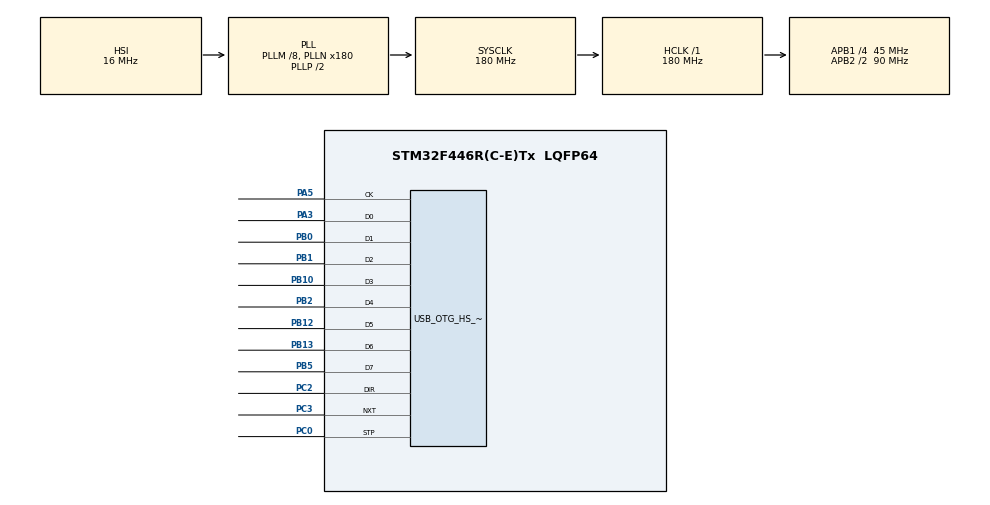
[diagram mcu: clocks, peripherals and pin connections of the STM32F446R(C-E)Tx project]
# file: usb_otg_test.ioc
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Mcu.Family=STM32F4
Mcu.Name=STM32F446R(C-E)Tx
Mcu.Package=LQFP64
NVIC.PriorityGroup=NVIC_PRIORITYGROUP_4
PA3.Mode=Device_HS
PA3.Signal=USB_OTG_HS_ULPI_D0
PA5.Mode=Device_HS
PA5.Signal=USB_OTG_HS_ULPI_CK
PB0.Mode=Device_HS
PB0.Signal=USB_OTG_HS_ULPI_D1
PB1.Mode=Device_HS
PB1.Signal=USB_OTG_HS_ULPI_D2
PB10.Mode=Device_HS
PB10.Signal=USB_OTG_HS_ULPI_D3
PB12.Mode=Device_HS
PB12.Signal=USB_OTG_HS_ULPI_D5
PB13.Mode=Device_HS
PB13.Signal=USB_OTG_HS_ULPI_D6
PB2.Mode=Device_HS
PB2.Signal=USB_OTG_HS_ULPI_D4
PB5.Mode=Device_HS
PB5.Signal=USB_OTG_HS_ULPI_D7
PC0.Mode=Device_HS
PC0.Signal=USB_OTG_HS_ULPI_STP
PC2.Mode=Device_HS
PC2.Signal=USB_OTG_HS_ULPI_DIR
PC3.Mode=Device_HS
PC3.Signal=USB_OTG_HS_ULPI_NXT
ProjectManager.HeapSize=0x200
ProjectManager.StackSize=0x400
ProjectManager.TargetToolchain=SW4STM32
RCC.AHBFreq_Value=180000000
RCC.APB1CLKDivider=RCC_HCLK_DIV4
RCC.APB1Freq_Value=45000000
RCC.APB1TimFreq_Value=90000000
RCC.APB2CLKDivider=RCC_HCLK_DIV2
RCC.APB2Freq_Value=90000000
RCC.APB2TimFreq_Value=180000000
RCC.CortexFreq_Value=180000000
RCC.HCLKFreq_Value=180000000
RCC.PLLM=8
RCC.PLLN=180
RCC.SYSCLKFreq_VALUE=180000000
RCC.SYSCLKSource=RCC_SYSCLKSOURCE_PLLCLK
RCC.USBFreq_Value=180000000
RCC.VCOOutputFreq_Value=360000000
USB_OTG_HS.DeviceSpeed-Device_HS=PCD_SPEED_FULL
USB_OTG_HS.VirtualMode-Device_HS=Device_HS
VP_TIM6_VS_ClockSourceINT.Mode=Enable_Timer
board=custom

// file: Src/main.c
/* USER CODE BEGIN Header */
/**
  ******************************************************************************
  * @file           : main.c
  * @brief          : Main program body
  ******************************************************************************
  * @attention
  *
  * <h2><center>&copy; Copyright (c) 2019 STMicroelectronics.
  * All rights reserved.</center></h2>
  *
  * This software component is licensed by ST under BSD 3-Clause license,
  * the "License"; You may not use this file except in compliance with the
  * License. You may obtain a copy of the License at:
  *                        opensource.org/licenses/BSD-3-Clause
  *
  ******************************************************************************
  */
/* USER CODE END Header */

#include "main.h"

TIM_HandleTypeDef htim6;

PCD_HandleTypeDef hpcd_USB_OTG_HS;

void SystemClock_Config(void);
static void MX_GPIO_Init(void);
static void MX_TIM6_Init(void);
static void MX_USB_OTG_HS_PCD_Init(void);

int main(void)
{

  /* MCU Configuration--------------------------------------------------------*/

  /* Reset of all peripherals, Initializes the Flash interface and the Systick. */
  HAL_Init();

  /* Configure the system clock */
  SystemClock_Config();

  /* Initialize all configured peripherals */
  MX_GPIO_Init();
  MX_TIM6_Init();
  MX_USB_OTG_HS_PCD_Init();
  /* USER CODE BEGIN 2 */
  HAL_TIM_Base_Start(&htim6);
  /* USER CODE END 2 */

  /* Infinite loop */
  while (1)
  {

  }
}

void SystemClock_Config(void)
{
  RCC_OscInitTypeDef RCC_OscInitStruct = {0};
  RCC_ClkInitTypeDef RCC_ClkInitStruct = {0};

  /** Configure the main internal regulator output voltage
  */
  __HAL_RCC_PWR_CLK_ENABLE();
  __HAL_PWR_VOLTAGESCALING_CONFIG(PWR_REGULATOR_VOLTAGE_SCALE1);
  /** Initializes the CPU, AHB and APB busses clocks
  */
  RCC_OscInitStruct.OscillatorType = RCC_OSCILLATORTYPE_HSI;
  RCC_OscInitStruct.HSIState = RCC_HSI_ON;
  RCC_OscInitStruct.HSICalibrationValue = RCC_HSICALIBRATION_DEFAULT;
  RCC_OscInitStruct.PLL.PLLState = RCC_PLL_ON;
  RCC_OscInitStruct.PLL.PLLSource = RCC_PLLSOURCE_HSI;
  RCC_OscInitStruct.PLL.PLLM = 8;
  RCC_OscInitStruct.PLL.PLLN = 180;
  RCC_OscInitStruct.PLL.PLLP = RCC_PLLP_DIV2;
  RCC_OscInitStruct.PLL.PLLQ = 2;
  RCC_OscInitStruct.PLL.PLLR = 2;
  if (HAL_RCC_OscConfig(&RCC_OscInitStruct) != HAL_OK)
  {
    Error_Handler();
  }
  /** Activate the Over-Drive mode
  */
  if (HAL_PWREx_EnableOverDrive() != HAL_OK)
  {
    Error_Handler();
  }
  /** Initializes the CPU, AHB and APB busses clocks
  */
  RCC_ClkInitStruct.ClockType = RCC_CLOCKTYPE_HCLK|RCC_CLOCKTYPE_SYSCLK
                              |RCC_CLOCKTYPE_PCLK1|RCC_CLOCKTYPE_PCLK2;
  RCC_ClkInitStruct.SYSCLKSource = RCC_SYSCLKSOURCE_PLLCLK;
  RCC_ClkInitStruct.AHBCLKDivider = RCC_SYSCLK_DIV1;
  RCC_ClkInitStruct.APB1CLKDivider = RCC_HCLK_DIV4;
  RCC_ClkInitStruct.APB2CLKDivider = RCC_HCLK_DIV2;

  if (HAL_RCC_ClockConfig(&RCC_ClkInitStruct, FLASH_LATENCY_5) != HAL_OK)
  {
    Error_Handler();
  }
}

static void MX_TIM6_Init(void)
{

  TIM_MasterConfigTypeDef sMasterConfig = {0};

  htim6.Instance = TIM6;
  htim6.Init.Prescaler = 0;
  htim6.Init.CounterMode = TIM_COUNTERMODE_UP;
  htim6.Init.Period = 0;
  htim6.Init.AutoReloadPreload = TIM_AUTORELOAD_PRELOAD_DISABLE;
  if (HAL_TIM_Base_Init(&htim6) != HAL_OK)
  {
    Error_Handler();
  }
  sMasterConfig.MasterOutputTrigger = TIM_TRGO_RESET;
  sMasterConfig.MasterSlaveMode = TIM_MASTERSLAVEMODE_DISABLE;
  if (HAL_TIMEx_MasterConfigSynchronization(&htim6, &sMasterConfig) != HAL_OK)
  {
    Error_Handler();
  }

}

static void MX_USB_OTG_HS_PCD_Init(void)
{

  hpcd_USB_OTG_HS.Instance = USB_OTG_HS;
  hpcd_USB_OTG_HS.Init.dev_endpoints = 8;
  hpcd_USB_OTG_HS.Init.speed = PCD_SPEED_FULL;
  hpcd_USB_OTG_HS.Init.dma_enable = DISABLE;
  hpcd_USB_OTG_HS.Init.phy_itface = USB_OTG_ULPI_PHY;
  hpcd_USB_OTG_HS.Init.Sof_enable = DISABLE;
  hpcd_USB_OTG_HS.Init.low_power_enable = DISABLE;
  hpcd_USB_OTG_HS.Init.lpm_enable = DISABLE;
  hpcd_USB_OTG_HS.Init.vbus_sensing_enable = DISABLE;
  hpcd_USB_OTG_HS.Init.use_dedicated_ep1 = DISABLE;
  hpcd_USB_OTG_HS.Init.use_external_vbus = DISABLE;
  if (HAL_PCD_Init(&hpcd_USB_OTG_HS) != HAL_OK)
  {
    Error_Handler();
  }

}

static void MX_GPIO_Init(void)
{

  /* GPIO Ports Clock Enable */
  __HAL_RCC_GPIOC_CLK_ENABLE();
  __HAL_RCC_GPIOA_CLK_ENABLE();
  __HAL_RCC_GPIOB_CLK_ENABLE();

}

void Error_Handler(void)
{
}

/************************ (C) COPYRIGHT STMicroelectronics *****END OF FILE****/
